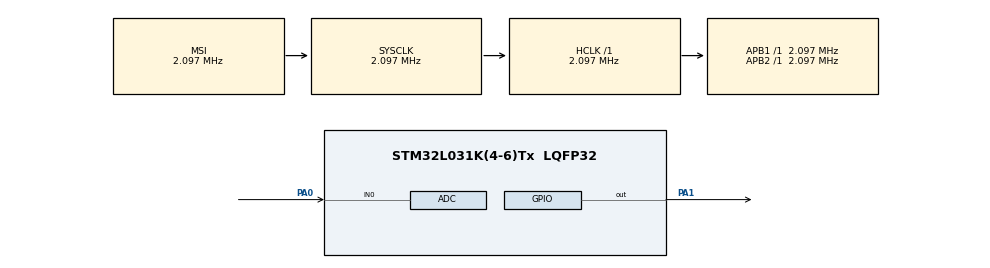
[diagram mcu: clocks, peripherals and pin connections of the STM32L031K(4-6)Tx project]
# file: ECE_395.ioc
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Mcu.Family=STM32L0
Mcu.Name=STM32L031K(4-6)Tx
Mcu.Package=LQFP32
PA0-CK_IN.Signal=SharedAnalog_PA0
PA1.Signal=GPIO_Output
ProjectManager.HeapSize=0x200
ProjectManager.StackSize=0x400
ProjectManager.TargetToolchain=STM32CubeIDE
RCC.AHBFreq_Value=2097000
RCC.APB1Freq_Value=2097000
RCC.APB1TimFreq_Value=2097000
RCC.APB2Freq_Value=2097000
RCC.APB2TimFreq_Value=2097000
RCC.HSE_VALUE=8000000
RCC.HSI16_VALUE=16000000
RCC.HSI_VALUE=16000000
RCC.LSE_VALUE=32768
RCC.MSI_VALUE=2097000
RCC.SYSCLKFreq_VALUE=2097000
RCC.VCOOutputFreq_Value=48000000
SH.SharedAnalog_PA0.0=GPIO_Analog
SH.SharedAnalog_PA0.1=ADC_IN0,IN0
board=custom

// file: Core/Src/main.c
/* USER CODE BEGIN Header */
/**
  ******************************************************************************
  * @file           : main.c
  * @brief          : Main program body
  ******************************************************************************
  * @attention
  *
  * Copyright (c) 2025 STMicroelectronics.
  * All rights reserved.
  *
  * This software is licensed under terms that can be found in the LICENSE file
  * in the root directory of this software component.
  * If no LICENSE file comes with this software, it is provided AS-IS.
  *
  ******************************************************************************
  */
/* USER CODE END Header */
#include "main.h"

/* USER CODE BEGIN PD */
#define VREF 3.3f
#define ADC_RESOLUTION 4095.0f
#define THRESHOLD_VOLTAGE 2.0f
#define THRESHOLD_ADC_VALUE ((uint16_t)((THRESHOLD_VOLTAGE / VREF) * ADC_RESOLUTION))
/* USER CODE END PD */

ADC_HandleTypeDef hadc;

void SystemClock_Config(void);
static void MX_GPIO_Init(void);
static void MX_ADC_Init(void);
/* USER CODE BEGIN PFP */
uint16_t Read_ADC(void);
/* USER CODE END PFP */

int main(void)
{

  /* USER CODE BEGIN 1 */
  uint16_t adc_value = 0;
  /* USER CODE END 1 */

  /* MCU Configuration--------------------------------------------------------*/

  /* Reset of all peripherals, Initializes the Flash interface and the Systick. */
  HAL_Init();

  /* Configure the system clock */
  SystemClock_Config();

  /* Initialize all configured peripherals */
  MX_GPIO_Init();
  MX_ADC_Init();
  /* USER CODE BEGIN 2 */
  HAL_ADCEx_Calibration_Start(&hadc, ADC_SINGLE_ENDED);
  /* USER CODE END 2 */

  /* Infinite loop */
  /* USER CODE BEGIN WHILE */
  while (1)
  {
    adc_value = Read_ADC();

    if (adc_value >= THRESHOLD_ADC_VALUE)
    {
      HAL_GPIO_WritePin(GPIOA, GPIO_PIN_1, GPIO_PIN_SET);
    }
    else
    {
      HAL_GPIO_WritePin(GPIOA, GPIO_PIN_1, GPIO_PIN_RESET);
    }
    /* USER CODE END WHILE */

  }
}

void SystemClock_Config(void)
{
  RCC_OscInitTypeDef RCC_OscInitStruct = {0};
  RCC_ClkInitTypeDef RCC_ClkInitStruct = {0};

  /** Configure the main internal regulator output voltage
  */
  __HAL_PWR_VOLTAGESCALING_CONFIG(PWR_REGULATOR_VOLTAGE_SCALE1);

  /** Initializes the RCC Oscillators according to the specified parameters
  * in the RCC_OscInitTypeDef structure.
  */
  RCC_OscInitStruct.OscillatorType = RCC_OSCILLATORTYPE_MSI;
  RCC_OscInitStruct.MSIState = RCC_MSI_ON;
  RCC_OscInitStruct.MSICalibrationValue = 0;
  RCC_OscInitStruct.MSIClockRange = RCC_MSIRANGE_5;
  RCC_OscInitStruct.PLL.PLLState = RCC_PLL_NONE;
  if (HAL_RCC_OscConfig(&RCC_OscInitStruct) != HAL_OK)
  {
    Error_Handler();
  }

  /** Initializes the CPU, AHB and APB buses clocks
  */
  RCC_ClkInitStruct.ClockType = RCC_CLOCKTYPE_HCLK|RCC_CLOCKTYPE_SYSCLK
                              |RCC_CLOCKTYPE_PCLK1|RCC_CLOCKTYPE_PCLK2;
  RCC_ClkInitStruct.SYSCLKSource = RCC_SYSCLKSOURCE_MSI;
  RCC_ClkInitStruct.AHBCLKDivider = RCC_SYSCLK_DIV1;
  RCC_ClkInitStruct.APB1CLKDivider = RCC_HCLK_DIV1;
  RCC_ClkInitStruct.APB2CLKDivider = RCC_HCLK_DIV1;

  if (HAL_RCC_ClockConfig(&RCC_ClkInitStruct, FLASH_LATENCY_0) != HAL_OK)
  {
    Error_Handler();
  }
}

static void MX_ADC_Init(void)
{

  ADC_ChannelConfTypeDef sConfig = {0};

  /** Configure the global features of the ADC (Clock, Resolution, Data Alignment and number of conversion)
  */
  hadc.Instance = ADC1;
  hadc.Init.OversamplingMode = DISABLE;
  hadc.Init.ClockPrescaler = ADC_CLOCK_SYNC_PCLK_DIV1;
  hadc.Init.Resolution = ADC_RESOLUTION_12B;
  hadc.Init.SamplingTime = ADC_SAMPLETIME_1CYCLE_5;
  hadc.Init.ScanConvMode = ADC_SCAN_DIRECTION_FORWARD;
  hadc.Init.DataAlign = ADC_DATAALIGN_RIGHT;
  hadc.Init.ContinuousConvMode = DISABLE;
  hadc.Init.DiscontinuousConvMode = DISABLE;
  hadc.Init.ExternalTrigConvEdge = ADC_EXTERNALTRIGCONVEDGE_NONE;
  hadc.Init.ExternalTrigConv = ADC_SOFTWARE_START;
  hadc.Init.DMAContinuousRequests = DISABLE;
  hadc.Init.EOCSelection = ADC_EOC_SINGLE_CONV;
  hadc.Init.Overrun = ADC_OVR_DATA_PRESERVED;
  hadc.Init.LowPowerAutoWait = DISABLE;
  hadc.Init.LowPowerFrequencyMode = ENABLE;
  hadc.Init.LowPowerAutoPowerOff = DISABLE;
  if (HAL_ADC_Init(&hadc) != HAL_OK)
  {
    Error_Handler();
  }

  /** Configure for the selected ADC regular channel to be converted.
  */
  sConfig.Channel = ADC_CHANNEL_0;
  sConfig.Rank = ADC_RANK_CHANNEL_NUMBER;
  if (HAL_ADC_ConfigChannel(&hadc, &sConfig) != HAL_OK)
  {
    Error_Handler();
  }

}

static void MX_GPIO_Init(void)
{
  GPIO_InitTypeDef GPIO_InitStruct = {0};

  /* GPIO Ports Clock Enable */
  __HAL_RCC_GPIOA_CLK_ENABLE();

  /*Configure GPIO pin Output Level */
  HAL_GPIO_WritePin(GPIOA, GPIO_PIN_1, GPIO_PIN_RESET);

  /*Configure GPIO pin : PA1 */
  GPIO_InitStruct.Pin = GPIO_PIN_1;
  GPIO_InitStruct.Mode = GPIO_MODE_OUTPUT_PP;
  GPIO_InitStruct.Pull = GPIO_NOPULL;
  GPIO_InitStruct.Speed = GPIO_SPEED_FREQ_LOW;
  HAL_GPIO_Init(GPIOA, &GPIO_InitStruct);

}

/* USER CODE BEGIN 4 */
uint16_t Read_ADC(void)
{
  uint16_t adc_value = 0;

  HAL_ADC_Start(&hadc);

  if (HAL_ADC_PollForConversion(&hadc, 10) == HAL_OK)
  {
    adc_value = HAL_ADC_GetValue(&hadc);
  }

  HAL_ADC_Stop(&hadc);

  return adc_value;
}
/* USER CODE END 4 */

void Error_Handler(void)
{
  __disable_irq();
  while (1)
  {
  }
}
